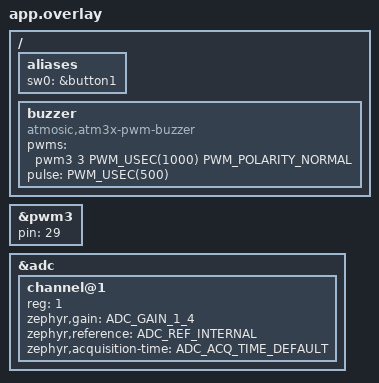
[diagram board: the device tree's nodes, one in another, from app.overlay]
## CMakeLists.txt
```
# Copyright (c) 2025 Atmosic
#
# SPDX-License-Identifier: Apache-2.0

cmake_minimum_required(VERSION 3.20.0)

find_package(Zephyr REQUIRED HINTS $ENV{ZEPHYR_BASE})
project(combo_tag)

target_sources(app PRIVATE
  src/main.c
)

add_subdirectory(src/platform)
```

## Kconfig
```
# Copyright (c) 2025 Atmosic
#
# SPDX-License-Identifier: Apache-2.0

source "Kconfig.zephyr"

module = COMBO_TAG
module-str = combo_tag
source "subsys/logging/Kconfig.template.log_config"

config FMNA_DEV_CUSTOM_BT_ADDR
	bool "Enable custom Bluetooth device address for testing or development purposes"

config FMNA_DEV_CUSTOM_BT_ADDR_VALUE
	string "Custom Bluetooth address (MAC format: XX:XX:XX:XX:XX:XX)"
	depends on FMNA_DEV_CUSTOM_BT_ADDR
	default "ED:15:48:87:6E:EF"

config FMNA_PRODUCT_DATA
	string "FMNA Product Data"
	default "DFECEFF1E1FF54DB"

config FMNA_ACCESSORY_CATEGORY
	int "FMNA Accessory Category"
	range 0 255
	default 129

config FMNA_ACCESSORY_CAPABILITY
	int "FMNA Accessory Capability Bit Mask"
	range 0 65535
	default 31
	help
	  Bit 0: Supports play sound
	  Bit 1: Supports motion detector UT
	  Bit 2: Supports serial number lookup by NFC
	  Bit 3: Supports serial number lookup by BLE
	  Bit 4: Supports firmware update service

config FMNA_BATTERY_TYPE
	int "FMNA Battery Type"
	range 0 255
	default 1
	help
	  0: Powered
	  1: Non-rechargeable battery
	  2: Rechargeable battery

config FMNA_PID
	int "FMNA Product ID"
	range 0 65535
	default 51966

config FMNA_MANUFACTURER_NAME
	string "FMNA Manufacturer Name"
	default "Osprey"

config FMNA_MODEL_NAME
	string "FMNA Model Name"
	default "Bike"

config FMNA_HARDWARE_VERSION
	string "FMNA Hardware Version"
	default "1"

config FMNA_VERSION_MAJOR
	int "FMNA Version Major"
	range 0 65535
	default 1

config FMNA_VERSION_MINOR
	int "FMNA Version Minor"
	range 0 65535
	default 0

config FMNA_VERSION_REVISION
	int "FMNA Version Revision"
	range 0 65535
	default 18

config COMBO_TAG_BTN_POWER_CTRL
	bool "Enable button power on/off control"
	select PM
	select HWINFO
	help
	  Enable button control for power on/off functionality.
	  2s press to power on/off with LED indication.

config COMBO_TAG_BTN_FACTORY_RESET
	bool "Enable factory reset with long press button"
	help
	  Long press button for 10 secs to trigger factory reset in power on
	  state. Pressing 2 secs would trigger power off key first and keep
	  pressing until 10 secs would trigger factory reset then enter off state.

config COMBO_TAG_BTN_BATT_REPORT
	bool "Enable battery level detection with button"
	help
	  Quick press button 5 times to show battery level with LED indication.

config COMBO_TAG_LED_IND
	bool "Enable LED indication for state and button"
	select LED
	help
	  Power on: Green LED blinks 3 times
	  Power off: Red LED blinks 3 times
	  Pairing mode: Green blink -> Red blink every 5 secs
	  Operation mode: Green LED blinks every 20 secs
	  Battery Status:
	    >90% 5 GREEN blinks
	    >60% 4 GREEN blinks
	    >30% 3 GREEN blinks
	    >10% 2 GREEN blinks
	    <=10% single GREEN blink

config COMBO_TAG_SOC_OFF_TIMEOUT
	int "SOC off timeout in pairing mode (seconds)"
	range 0 300
	default 0
	help
	  Timeout in seconds to enter SOC_off mode when in pairing mode.
	  Set to 0 to disable timeout.

config COMBO_TAG_AUDIO_FEEDBACK
	bool "Enable audio feedback for factory reset"
	select ATM_BUZZER
	help
	  Enable audio feedback when factory reset is triggered.
```

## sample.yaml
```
sample:
  description: FMNA and FMDN Combo Tag
  name: FMNA and FMDN Combo Tag
common:
  sysbuild: true
  harness: console
  harness_config:
    type: multi_line
    regex:
      - "fmna: Advertising successfully started"
      - "fp: FP Discoverable Advertising successfully started"
tests:
  applications.combo_tag.atm:
    tags: fp_tag atm33 no_mcuboot
    extra_args:
      - SB_CONFIG_SPE=y
      - SB_CONFIG_ATMWSTK_FULL=y
      - SB_ATM_DTS_EXTRA_CPPFLAGS="-DATM_STORAGE_SIZE=0x1000;-DDFU_IN_FLASH"
    extra_configs:
      - CONFIG_ATM_SOC_ALLOW="ATM33"
  applications.combo_tag.atm.atm34:
    tags: fp_tag atm34 no_mcuboot
    extra_args:
      - SB_CONFIG_SPE=y
      - SB_CONFIG_ATMWSTK_CPD200=y
      - SB_ATM_DTS_EXTRA_CPPFLAGS="-DATM_STORAGE_SIZE=0x1000"
    extra_configs:
      - CONFIG_ATM_SOC_ALLOW="ATM34"
  applications.combo_tag.atm.atm34.mcuboot.flash_xip:
    tags: combo_tag atm34 mcuboot flash_xip
    extra_args:
      - SB_CONFIG_SPE=y
      - SB_CONFIG_BOOTLOADER_MCUBOOT=y
      - SB_CONFIG_BOOT_SIGNATURE_TYPE_ECDSA_P256=y
      - SB_CONFIG_ATMWSTK_PD50=y
      - SB_ATM_DTS_EXTRA_CPPFLAGS="-DRUN_IN_FLASH=2"
      - mcuboot_CONFIG_UPDATEABLE_IMAGE_NUMBER=2
    extra_configs:
      - CONFIG_ATM_SOC_ALLOW="ATM34"
  applications.combo_tag.atm.atm34.mcuboot.flash_xip.overwrite:
    tags: combo_tag atm34 mcuboot flash_xip overwrite
    extra_args:
      - SB_CONFIG_SPE=y
      - SB_CONFIG_BOOTLOADER_MCUBOOT=y
      - SB_CONFIG_BOOT_SIGNATURE_TYPE_ECDSA_P256=y
      - SB_CONFIG_MCUBOOT_MODE_OVERWRITE_ONLY=y
      - SB_CONFIG_ATMWSTK_PD50=y
      - SB_ATM_DTS_EXTRA_CPPFLAGS="-DATM_APP_FLASH_XIP;-DATM_MCUBOOT_SCRATCH_SIZE=0"
      - mcuboot_CONFIG_UPDATEABLE_IMAGE_NUMBER=2
      - mcuboot_CONFIG_MCUBOOT_VERIFY_IMG_ADDRESS=n
    extra_configs:
      - CONFIG_ATM_SOC_ALLOW="ATM34"
```

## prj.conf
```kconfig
# Let main thread priority lower than app work queue thread
CONFIG_MAIN_THREAD_PRIORITY=2
# Increased stack for fmna and fp usage
CONFIG_SYSTEM_WORKQUEUE_STACK_SIZE=2048
CONFIG_MAIN_STACK_SIZE=2048

CONFIG_ASSERT=y

CONFIG_BT=y
CONFIG_LOG=y
CONFIG_LOG_MODE_IMMEDIATE=y
CONFIG_BT_SMP=y
CONFIG_BT_SMP_SC_PAIR_ONLY=n
CONFIG_BT_PERIPHERAL=y
CONFIG_BT_DIS=y
CONFIG_BT_ATT_PREPARE_COUNT=5

# GATT TX Power service
CONFIG_BT_TPS=y

CONFIG_BT_DEVICE_NAME="Atmosic FMNA and FMDN combo demo tag"
CONFIG_BT_DEVICE_APPEARANCE=576

CONFIG_BT_KEYS_OVERWRITE_OLDEST=y
CONFIG_BT_SETTINGS=y
CONFIG_BT_EXT_ADV=y
CONFIG_BT_GATT_SERVICE_CHANGED=n
CONFIG_BT_ATT_ERR_TO_STR=y
# BT_L2CAP_RX_MTU = CONFIG_BT_BUF_ACL_RX_SIZE - BT_L2CAP_HDR_SIZE
CONFIG_BT_BUF_ACL_RX_SIZE=516
CONFIG_BT_L2CAP_TX_MTU=512
CONFIG_BT_GATT_ENFORCE_SUBSCRIPTION=n
CONFIG_BT_RX_STACK_SIZE=2560
CONFIG_BT_PERIPHERAL_PREF_MIN_INT=760
CONFIG_BT_PERIPHERAL_PREF_MAX_INT=800
CONFIG_BT_PERIPHERAL_PREF_LATENCY=0
CONFIG_BT_PERIPHERAL_PREF_TIMEOUT=800

# Flash
CONFIG_FLASH=y
CONFIG_FLASH_PAGE_LAYOUT=y
CONFIG_FLASH_MAP=y
CONFIG_NVS=y
CONFIG_SETTINGS=y
CONFIG_MPU_ALLOW_FLASH_WRITE=y

CONFIG_LOG_MODE_IMMEDIATE=y

# Memory optimization
CONFIG_BT_BUF_EVT_DISCARDABLE_COUNT=1

# Battery
CONFIG_ADC=y
CONFIG_BATT_MODEL_COIN=y

# PWM buzzer
# CONFIG_ATM_BUZZER=y

CONFIG_PM=y

# FMNA tag
CONFIG_ATM_FMNA=y
CONFIG_ATM_FMNA_LIB=y
CONFIG_MAX_TX_PWR=4

# FP tag
CONFIG_ATM_GFP=y
CONFIG_ATM_GFP_MUTLIMODE_TAG=y

# Enable debug
# CONFIG_COMBO_TAG_LOG_LEVEL_DBG=y
# CONFIG_ATM_GFPS_LOG_LEVEL_DBG=y
# CONFIG_ATM_DULT_LOG_LEVEL_DBG=y

# Combo tag
#default fmna (4) + fp (4)
CONFIG_BT_ID_MAX=8
#default fmna (4) + fp (4)
CONFIG_BT_BUF_ACL_RX_COUNT_EXTRA=1
#default fmna (2) + fp (2)
CONFIG_BT_EXT_ADV_MAX_ADV_SET=4
#default fmna (3) + fp (3)
CONFIG_BT_MAX_CONN=6
#default fmna (2) + fp (2)
CONFIG_BT_BUF_EVT_RX_COUNT=4
#default fmna (3) + fp (3)
CONFIG_BT_MAX_PAIRED=6
```

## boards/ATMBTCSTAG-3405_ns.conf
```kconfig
# Copyright (c) 2025 Atmosic
#
# SPDX-License-Identifier: Apache-2.0

#PMU Watch dog would be trigger per 900 sec.
CONFIG_ATM_SOCOFF_DURATION_SEC=900

# Enable button power control
CONFIG_COMBO_TAG_BTN_POWER_CTRL=y

# Enable factory reset with long press button
CONFIG_COMBO_TAG_BTN_FACTORY_RESET=y

# Enable battery level detection with button
CONFIG_COMBO_TAG_BTN_BATT_REPORT=y

# Enable LED indication
CONFIG_COMBO_TAG_LED_IND=y

# Set SOC off timeout to 60 seconds (1 minute)
CONFIG_COMBO_TAG_SOC_OFF_TIMEOUT=60

# Enable audio feedback for factory reset
CONFIG_COMBO_TAG_AUDIO_FEEDBACK=y
```

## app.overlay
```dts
/* Copyright (c) 2025 Atmosic
 *
 * SPDX-License-Identifier: Apache-2.0
 */

/ {
	aliases {
		sw0 = &button1;
	};
	buzzer: buzzer {
		compatible = "atmosic,atm3x-pwm-buzzer";
		pwms = <&pwm3 3 PWM_USEC(1000) PWM_POLARITY_NORMAL>;
		pulse = <PWM_USEC(500)>;
	};
};

&pwm3 {
	pin = <29>;
	status = "okay";
};

&adc {
	#address-cells = <1>;
	#size-cells = <0>;

	channel@1 {
		reg = <1>;
		zephyr,gain = "ADC_GAIN_1_4";
		zephyr,reference = "ADC_REF_INTERNAL";
		zephyr,acquisition-time = <ADC_ACQ_TIME_DEFAULT>;
	};
};
```

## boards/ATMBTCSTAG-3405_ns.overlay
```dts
/* Copyright (c) 2025 Atmosic
 *
 * SPDX-License-Identifier: Apache-2.0
 */

/ {
	buzzer: buzzer {
		compatible = "atmosic,atm3x-pwm-buzzer";
		pwms = <&pwm1 1 PWM_USEC(1000) PWM_POLARITY_NORMAL>;
		pulse = <PWM_USEC(500)>;
	};
};

&cpu0 {
	cpu-power-states = <&idle &sleep &retain &hibernate &soc_off>;
};

&adc {
	#address-cells = <1>;
	#size-cells = <0>;

	channel@1 {
		reg = <1>;
		zephyr,gain = "ADC_GAIN_1_8";
		zephyr,reference = "ADC_REF_INTERNAL";
		zephyr,acquisition-time = <ADC_ACQ_TIME_DEFAULT>;
	};
};
```

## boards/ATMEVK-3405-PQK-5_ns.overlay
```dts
/* Copyright (c) 2025 Atmosic
 *
 * SPDX-License-Identifier: Apache-2.0
 */

/ {
	aliases {
		sw0 = &button1;
	};
	buzzer: buzzer {
		compatible = "pwm-buzzer";
		pwms = <&pwm7 7 PWM_USEC(1000) PWM_POLARITY_NORMAL>;
		pulse = <PWM_USEC(500)>;
	};
};

&pwm7 {
	pin = <7>;
	status = "okay";
};

&adc {
	#address-cells = <1>;
	#size-cells = <0>;

	channel@1 {
		reg = <1>;
		zephyr,gain = "ADC_GAIN_1_4";
		zephyr,reference = "ADC_REF_INTERNAL";
		zephyr,acquisition-time = <ADC_ACQ_TIME_DEFAULT>;
	};
};
```

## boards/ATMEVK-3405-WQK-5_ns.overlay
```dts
/* Copyright (c) 2025 Atmosic
 *
 * SPDX-License-Identifier: Apache-2.0
 */

/ {
	aliases {
		sw0 = &button1;
	};
	buzzer: buzzer {
		compatible = "atmosic,atm3x-pwm-buzzer";
		pwms = <&pwm7 7 PWM_USEC(1000) PWM_POLARITY_NORMAL>;
		pulse = <PWM_USEC(500)>;
	};
};

&pwm7 {
	pin = <7>;
	status = "okay";
};

&adc {
	#address-cells = <1>;
	#size-cells = <0>;

	channel@1 {
		reg = <1>;
		zephyr,gain = "ADC_GAIN_1_8";
		zephyr,reference = "ADC_REF_INTERNAL";
		zephyr,acquisition-time = <ADC_ACQ_TIME_DEFAULT>;
	};
};
```

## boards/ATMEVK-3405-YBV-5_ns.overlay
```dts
/* Copyright (c) 2025 Atmosic
 *
 * SPDX-License-Identifier: Apache-2.0
 */

/ {
	aliases {
		sw0 = &button1;
	};
	buzzer: buzzer {
		compatible = "pwm-buzzer";
		pwms = <&pwm3 3 PWM_USEC(1000) PWM_POLARITY_NORMAL>;
		pulse = <PWM_USEC(500)>;
	};
};

&pwm3 {
	pin = <29>;
	status = "okay";
};

&adc {
	#address-cells = <1>;
	#size-cells = <0>;

	channel@1 {
		reg = <1>;
		zephyr,gain = "ADC_GAIN_1_8";
		zephyr,reference = "ADC_REF_INTERNAL";
		zephyr,acquisition-time = <ADC_ACQ_TIME_DEFAULT>;
	};
};
```

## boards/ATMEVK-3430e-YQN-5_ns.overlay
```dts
/* Copyright (c) 2025 Atmosic
 *
 * SPDX-License-Identifier: Apache-2.0
 */

/ {
	aliases {
		sw0 = &button1;
	};
	buzzer: buzzer {
		compatible = "atmosic,atm3x-pwm-buzzer";
		pwms = <&pwm3 3 PWM_USEC(1000) PWM_POLARITY_NORMAL>;
		pulse = <PWM_USEC(500)>;
	};
};

&pwm3 {
	pin = <29>;
	status = "okay";
};

&adc {
	#address-cells = <1>;
	#size-cells = <0>;

	channel@1 {
		reg = <1>;
		zephyr,gain = "ADC_GAIN_1_8";
		zephyr,reference = "ADC_REF_INTERNAL";
		zephyr,acquisition-time = <ADC_ACQ_TIME_DEFAULT>;
	};
};
```

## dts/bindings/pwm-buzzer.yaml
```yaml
# Copyright (c) 2025 Atmosic
#
# SPDX-License-Identifier: Apache-2.0

description: PWM-driven buzzer.

compatible: "pwm-buzzer"

include: base.yaml

properties:
  pwms:
    required: true
    type: phandle-array
    description: PWM specifier driving the buzzer.

  pulse:
    required: true
    type: int
    description: pulse width (nanoseconds).
```

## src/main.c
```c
/**
 *******************************************************************************
 *
 * @file main.c
 *
 * @brief FMNA and FMDN Combo Tag application
 *
 * Copyright (C) Atmosic 2025
 *
 *******************************************************************************
 */

#include <zephyr/bluetooth/bluetooth.h>
#include <zephyr/logging/log.h>
#include <zephyr/kernel.h>
#include <zephyr/settings/settings.h>
#include <zephyr/pm/pm.h>
#include <zephyr/pm/policy.h>
#include "app_work_q.h"
#include "platform.h"
#include "platform_ctrl_button.h"

LOG_MODULE_REGISTER(combo_tag, CONFIG_COMBO_TAG_LOG_LEVEL);

static void combo_tag_init_work_handler(struct k_work *work)
{
	platform_init();
}

K_WORK_DEFINE(combo_tag_init, combo_tag_init_work_handler);

static void combo_tag_bt_ready(void)
{
	if (!bt_is_ready()) {
		LOG_ERR("bt_is_ready is not ready");
	}

	// defer combo_tag_platform init to fp_work_q
	atm_work_submit_to_app_work_q(&combo_tag_init);
}

int main(void)
{

	if (!platform_ctrl_button_init()) {
		LOG_INF("skip power on");
#ifdef CONFIG_PM
		pm_policy_state_lock_put(PM_STATE_SOFT_OFF, PM_ALL_SUBSTATES);
#endif
		return 0;
	}

	int err = bt_enable(NULL);
	if (err) {
		LOG_WRN("Bluetooth enabled failed (err %d)", err);
		return 0;
	}
	LOG_INF("Bluetooth initialized");

	if (IS_ENABLED(CONFIG_SETTINGS)) {
		settings_load();
	}

	combo_tag_bt_ready();

	return 0;
}
```
